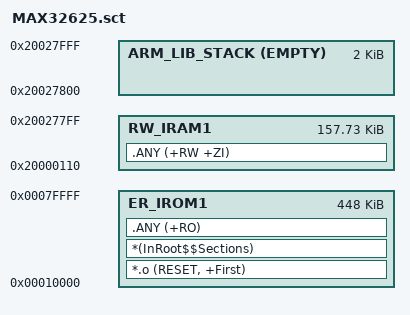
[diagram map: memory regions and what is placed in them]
#! armcc -E
; MAX32625
; 512KB FLASH (0x80000) @ 0x000000000
; 160KB RAM (0x28000) @ 0x20000000

#if !defined(MBED_APP_START)
    #define MBED_APP_START 0x00010000
#endif

#if !defined(MBED_APP_SIZE)
    #define MBED_APP_SIZE 0x00070000
#endif

#if !defined(MBED_BOOT_STACK_SIZE)
  #define MBED_BOOT_STACK_SIZE 0x800
#endif

#define Stack_Size MBED_BOOT_STACK_SIZE

LR_IROM1 MBED_APP_START MBED_APP_SIZE  {    ; load region size_region
    ER_IROM1 MBED_APP_START MBED_APP_SIZE  {  ; load address = execution address
        *.o (RESET, +First)
        *(InRoot$$Sections)
        .ANY (+RO)
    }

    ; [RAM] Vector table dynamic copy: 68 vectors * 4 bytes = 272 (0x110)
    RW_IRAM1 (0x20000000+0x110) (0x28000-0x110-Stack_Size)  {  ; RW data
        .ANY (+RW +ZI)
    }
    ARM_LIB_STACK (0x20000000+0x28000) EMPTY -Stack_Size { ; stack
    }
}
